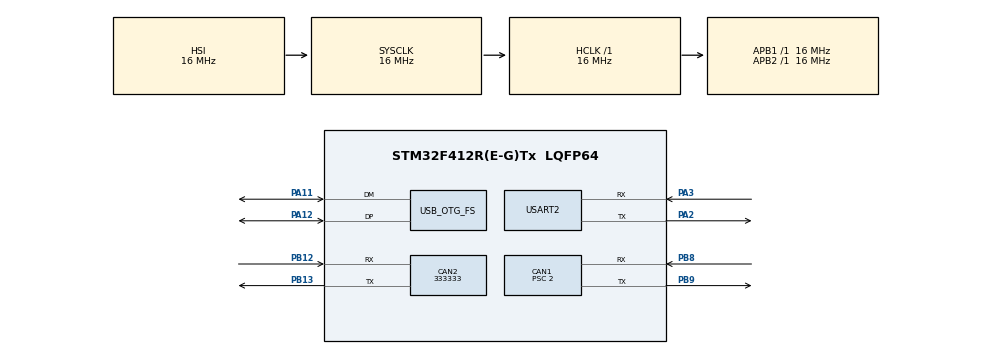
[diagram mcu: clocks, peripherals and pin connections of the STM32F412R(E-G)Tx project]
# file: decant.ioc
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CAN1.BS1=CAN_BS1_13TQ
CAN1.BS2=CAN_BS2_2TQ
CAN1.CalculateBaudRate=500000
CAN1.CalculateTimeBit=2000
CAN1.CalculateTimeQuantum=125.0
CAN1.NART=ENABLE
CAN1.Prescaler=2
CAN1.SJW=CAN_SJW_1TQ
CAN2.BS1=CAN_BS1_1TQ
CAN2.BS2=CAN_BS2_1TQ
CAN2.CalculateBaudRate=333333
CAN2.CalculateTimeBit=3000
CAN2.CalculateTimeQuantum=1000.0
FREERTOS.Tasks01=usbTransmit,32,128,StartDefaultTask,Default,NULL,Dynamic,NULL,NULL
FREERTOS.configUSE_NEWLIB_REENTRANT=1
Mcu.Family=STM32F4
Mcu.Name=STM32F412R(E-G)Tx
Mcu.Package=LQFP64
NVIC.CAN1_RX0_IRQn=true\:5\:0\:false\:false\:true\:true\:true\:true\:true
NVIC.OTG_FS_IRQn=true\:5\:0\:false\:false\:true\:true\:false\:true\:true
NVIC.PriorityGroup=NVIC_PRIORITYGROUP_4
NVIC.TIM6_IRQn=true\:15\:0\:false\:false\:true\:false\:false\:true\:true
NVIC.TimeBase=TIM6_IRQn
NVIC.TimeBaseIP=TIM6
PA11.Mode=Device_Only
PA11.Signal=USB_OTG_FS_DM
PA12.Mode=Device_Only
PA12.Signal=USB_OTG_FS_DP
PA13.Mode=JTAG_5_pins
PA13.Signal=SYS_JTMS-SWDIO
PA14.Mode=JTAG_5_pins
PA14.Signal=SYS_JTCK-SWCLK
PA15.Mode=JTAG_5_pins
PA15.Signal=SYS_JTDI
PA2.Mode=Asynchronous
PA2.Signal=USART2_TX
PA3.Mode=Asynchronous
PA3.Signal=USART2_RX
PB12.Mode=CAN_Activate
PB12.Signal=CAN2_RX
PB13.Mode=CAN_Activate
PB13.Signal=CAN2_TX
PB3.Mode=JTAG_5_pins
PB3.Signal=SYS_JTDO-SWO
PB4.Mode=JTAG_5_pins
PB4.Signal=SYS_JTRST
PB8.Mode=CAN_Activate
PB8.Signal=CAN1_RX
PB9.Mode=CAN_Activate
PB9.Signal=CAN1_TX
PC14-OSC32_IN.Mode=LSE-External-Oscillator
PC14-OSC32_IN.Signal=RCC_OSC32_IN
PC15-OSC32_OUT.Mode=LSE-External-Oscillator
PC15-OSC32_OUT.Signal=RCC_OSC32_OUT
PH0\ -\ OSC_IN.Mode=HSE-External-Oscillator
PH0\ -\ OSC_IN.Signal=RCC_OSC_IN
PH1\ -\ OSC_OUT.Mode=HSE-External-Oscillator
PH1\ -\ OSC_OUT.Signal=RCC_OSC_OUT
ProjectManager.HeapSize=0x200
ProjectManager.StackSize=0x400
ProjectManager.TargetToolchain=STM32CubeIDE
RCC.AHBFreq_Value=16000000
RCC.APB1Freq_Value=16000000
RCC.APB1TimFreq_Value=16000000
RCC.APB2Freq_Value=16000000
RCC.APB2TimFreq_Value=16000000
RCC.CortexFreq_Value=16000000
RCC.HCLKFreq_Value=16000000
RCC.PLLI2SM=20
RCC.PLLI2SQ=5
RCC.PLLM=15
RCC.PLLN=144
RCC.PLLQ=5
RCC.SYSCLKFreq_VALUE=16000000
RCC.USBFreq_Value=48000000
RCC.VCOOutputFreq_Value=240000000
USART2.VirtualMode=VM_ASYNC
USB_DEVICE.CLASS_NAME_FS=CDC
USB_DEVICE.VirtualMode=Cdc
USB_DEVICE.VirtualModeFS=Cdc_FS
USB_OTG_FS.VirtualMode=Device_Only
VP_FREERTOS_VS_CMSIS_V2.Mode=CMSIS_V2
VP_SYS_VS_tim6.Mode=TIM6
VP_USB_DEVICE_VS_USB_DEVICE_CDC_FS.Mode=CDC_FS
board=custom

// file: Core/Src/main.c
/* USER CODE BEGIN Header */
/**
  ******************************************************************************
  * @file           : main.c
  * @brief          : Main program body
  ******************************************************************************
  * @attention
  *
  * Copyright (c) 2023 STMicroelectronics.
  * All rights reserved.
  *
  * This software is licensed under terms that can be found in the LICENSE file
  * in the root directory of this software component.
  * If no LICENSE file comes with this software, it is provided AS-IS.
  *
  ******************************************************************************
  */
/* USER CODE END Header */
#include "main.h"
#include "cmsis_os.h"
#include "usb_device.h"

/* USER CODE BEGIN Includes */
#include "CANopen/canopen_driver.h"

/* USER CODE END Includes */

CAN_HandleTypeDef hcan1;
CAN_HandleTypeDef hcan2;

UART_HandleTypeDef huart2;

/* Definitions for usbTransmit */
osThreadId_t usbTransmitHandle;
const osThreadAttr_t usbTransmit_attributes = {
  .name = "usbTransmit",
  .stack_size = 128 * 4,
  .priority = (osPriority_t) osPriorityAboveNormal,
};

void SystemClock_Config(void);
static void MX_GPIO_Init(void);
static void MX_CAN1_Init(void);
static void MX_CAN2_Init(void);
static void MX_USART2_UART_Init(void);
void StartDefaultTask(void *argument);

int main(void)
{

  /* MCU Configuration--------------------------------------------------------*/

  /* Reset of all peripherals, Initializes the Flash interface and the Systick. */
  HAL_Init();

  /* Configure the system clock */
  SystemClock_Config();

  /* Initialize all configured peripherals */
  MX_GPIO_Init();
  MX_CAN1_Init();
  MX_CAN2_Init();
  MX_USART2_UART_Init();
  /* USER CODE BEGIN 2 */
  HAL_UART_Transmit(&huart2, (uint8_t*)"Started", sizeof("Started"), 10);

  /* USER CODE END 2 */

  /* Init scheduler */
  osKernelInitialize();

  /* Create the thread(s) */
  /* creation of usbTransmit */
  usbTransmitHandle = osThreadNew(StartDefaultTask, NULL, &usbTransmit_attributes);

  /* Start scheduler */
  osKernelStart();
  /* We should never get here as control is now taken by the scheduler */
  /* Infinite loop */
  while (1)
  {

  }
}

void SystemClock_Config(void)
{
  RCC_OscInitTypeDef RCC_OscInitStruct = {0};
  RCC_ClkInitTypeDef RCC_ClkInitStruct = {0};

  /** Configure the main internal regulator output voltage
  */
  __HAL_RCC_PWR_CLK_ENABLE();
  __HAL_PWR_VOLTAGESCALING_CONFIG(PWR_REGULATOR_VOLTAGE_SCALE1);

  /** Initializes the RCC Oscillators according to the specified parameters
  * in the RCC_OscInitTypeDef structure.
  */
  RCC_OscInitStruct.OscillatorType = RCC_OSCILLATORTYPE_HSI|RCC_OSCILLATORTYPE_HSE;
  RCC_OscInitStruct.HSEState = RCC_HSE_ON;
  RCC_OscInitStruct.HSIState = RCC_HSI_ON;
  RCC_OscInitStruct.HSICalibrationValue = RCC_HSICALIBRATION_DEFAULT;
  RCC_OscInitStruct.PLL.PLLState = RCC_PLL_ON;
  RCC_OscInitStruct.PLL.PLLSource = RCC_PLLSOURCE_HSE;
  RCC_OscInitStruct.PLL.PLLM = 15;
  RCC_OscInitStruct.PLL.PLLN = 144;
  RCC_OscInitStruct.PLL.PLLP = RCC_PLLP_DIV2;
  RCC_OscInitStruct.PLL.PLLQ = 5;
  RCC_OscInitStruct.PLL.PLLR = 2;
  if (HAL_RCC_OscConfig(&RCC_OscInitStruct) != HAL_OK)
  {
    Error_Handler();
  }

  /** Initializes the CPU, AHB and APB buses clocks
  */
  RCC_ClkInitStruct.ClockType = RCC_CLOCKTYPE_HCLK|RCC_CLOCKTYPE_SYSCLK
                              |RCC_CLOCKTYPE_PCLK1|RCC_CLOCKTYPE_PCLK2;
  RCC_ClkInitStruct.SYSCLKSource = RCC_SYSCLKSOURCE_HSI;
  RCC_ClkInitStruct.AHBCLKDivider = RCC_SYSCLK_DIV1;
  RCC_ClkInitStruct.APB1CLKDivider = RCC_HCLK_DIV1;
  RCC_ClkInitStruct.APB2CLKDivider = RCC_HCLK_DIV1;

  if (HAL_RCC_ClockConfig(&RCC_ClkInitStruct, FLASH_LATENCY_0) != HAL_OK)
  {
    Error_Handler();
  }
}

static void MX_CAN1_Init(void)
{

  hcan1.Instance = CAN1;
  hcan1.Init.Prescaler = 2;
  hcan1.Init.Mode = CAN_MODE_NORMAL;
  hcan1.Init.SyncJumpWidth = CAN_SJW_1TQ;
  hcan1.Init.TimeSeg1 = CAN_BS1_13TQ;
  hcan1.Init.TimeSeg2 = CAN_BS2_2TQ;
  hcan1.Init.TimeTriggeredMode = DISABLE;
  hcan1.Init.AutoBusOff = DISABLE;
  hcan1.Init.AutoWakeUp = DISABLE;
  hcan1.Init.AutoRetransmission = ENABLE;
  hcan1.Init.ReceiveFifoLocked = DISABLE;
  hcan1.Init.TransmitFifoPriority = DISABLE;
  if (HAL_CAN_Init(&hcan1) != HAL_OK)
  {
    Error_Handler();
  }

}

static void MX_CAN2_Init(void)
{

  hcan2.Instance = CAN2;
  hcan2.Init.Prescaler = 16;
  hcan2.Init.Mode = CAN_MODE_NORMAL;
  hcan2.Init.SyncJumpWidth = CAN_SJW_1TQ;
  hcan2.Init.TimeSeg1 = CAN_BS1_1TQ;
  hcan2.Init.TimeSeg2 = CAN_BS2_1TQ;
  hcan2.Init.TimeTriggeredMode = DISABLE;
  hcan2.Init.AutoBusOff = DISABLE;
  hcan2.Init.AutoWakeUp = DISABLE;
  hcan2.Init.AutoRetransmission = DISABLE;
  hcan2.Init.ReceiveFifoLocked = DISABLE;
  hcan2.Init.TransmitFifoPriority = DISABLE;
  if (HAL_CAN_Init(&hcan2) != HAL_OK)
  {
    Error_Handler();
  }

}

static void MX_USART2_UART_Init(void)
{

  huart2.Instance = USART2;
  huart2.Init.BaudRate = 115200;
  huart2.Init.WordLength = UART_WORDLENGTH_8B;
  huart2.Init.StopBits = UART_STOPBITS_1;
  huart2.Init.Parity = UART_PARITY_NONE;
  huart2.Init.Mode = UART_MODE_TX_RX;
  huart2.Init.HwFlowCtl = UART_HWCONTROL_NONE;
  huart2.Init.OverSampling = UART_OVERSAMPLING_16;
  if (HAL_UART_Init(&huart2) != HAL_OK)
  {
    Error_Handler();
  }

}

static void MX_GPIO_Init(void)
{

  /* GPIO Ports Clock Enable */
  __HAL_RCC_GPIOC_CLK_ENABLE();
  __HAL_RCC_GPIOH_CLK_ENABLE();
  __HAL_RCC_GPIOA_CLK_ENABLE();
  __HAL_RCC_GPIOB_CLK_ENABLE();

}

void StartDefaultTask(void *argument)
{
  /* init code for USB_DEVICE */
  MX_USB_DEVICE_Init();
  /* USER CODE BEGIN 5 */
  CANopen_init(&hcan1, &huart2);
  /* Infinite loop */
  for(;;)
  {
    CANopen_Queue_Process();
    osDelay(1);
  }
  /* USER CODE END 5 */
}

void HAL_TIM_PeriodElapsedCallback(TIM_HandleTypeDef *htim)
{
  if (htim->Instance == TIM6) {
    HAL_IncTick();
  }
}

void Error_Handler(void)
{
  /* USER CODE BEGIN Error_Handler_Debug */
  /* User can add his own implementation to report the HAL error return state */
  __disable_irq();
  HAL_UART_Transmit(&huart2, (uint8_t*)"ERROR", sizeof("ERROR"), 10);
  while (1)
  {
  }
  /* USER CODE END Error_Handler_Debug */
}
